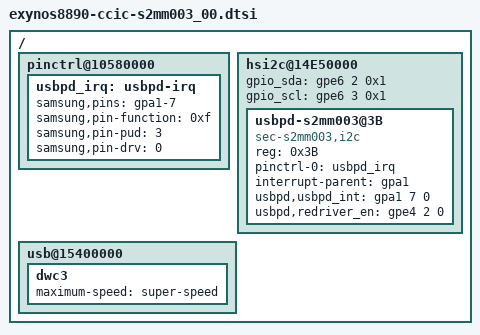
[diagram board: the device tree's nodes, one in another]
/*
 * SAMSUNG Hero Type C S2MM003 CCIC Device Tree Source
 *
 * Copyright (c) 2015 Samsung Electronics Co., Ltd.
 *		http://www.samsung.com
 *
 * This program is free software; you can redistribute it and/or modify
 * it under the terms of the GNU General Public License version 2 as
 * published by the Free Software Foundation.
*/

/ {
	pinctrl@10580000 {
		usbpd_irq: usbpd-irq {
			samsung,pins = "gpa1-7";
			samsung,pin-function = <0xf>;
			samsung,pin-pud = <3>;
			samsung,pin-drv = <0>;
		};
	};
	hsi2c@14E50000 {
		status = "okay";
		gpio_sda= <&gpe6 2 0x1>;
		gpio_scl= <&gpe6 3 0x1>;
        /*
		samsung,hs-mode;
        */
		usbpd-s2mm003@3B {
			compatible = "sec-s2mm003,i2c";
			reg = <0x3B>;
			pinctrl-names = "default";
			pinctrl-0 = <&usbpd_irq>;
			interrupt-parent = <&gpa1>;
			usbpd,usbpd_int = <&gpa1 7 0>;
			usbpd,redriver_en = <&gpe4 2 0>;
		};
	};

	usb@15400000 {
		dwc3 {
			maximum-speed = "super-speed";
		};
	};
};
